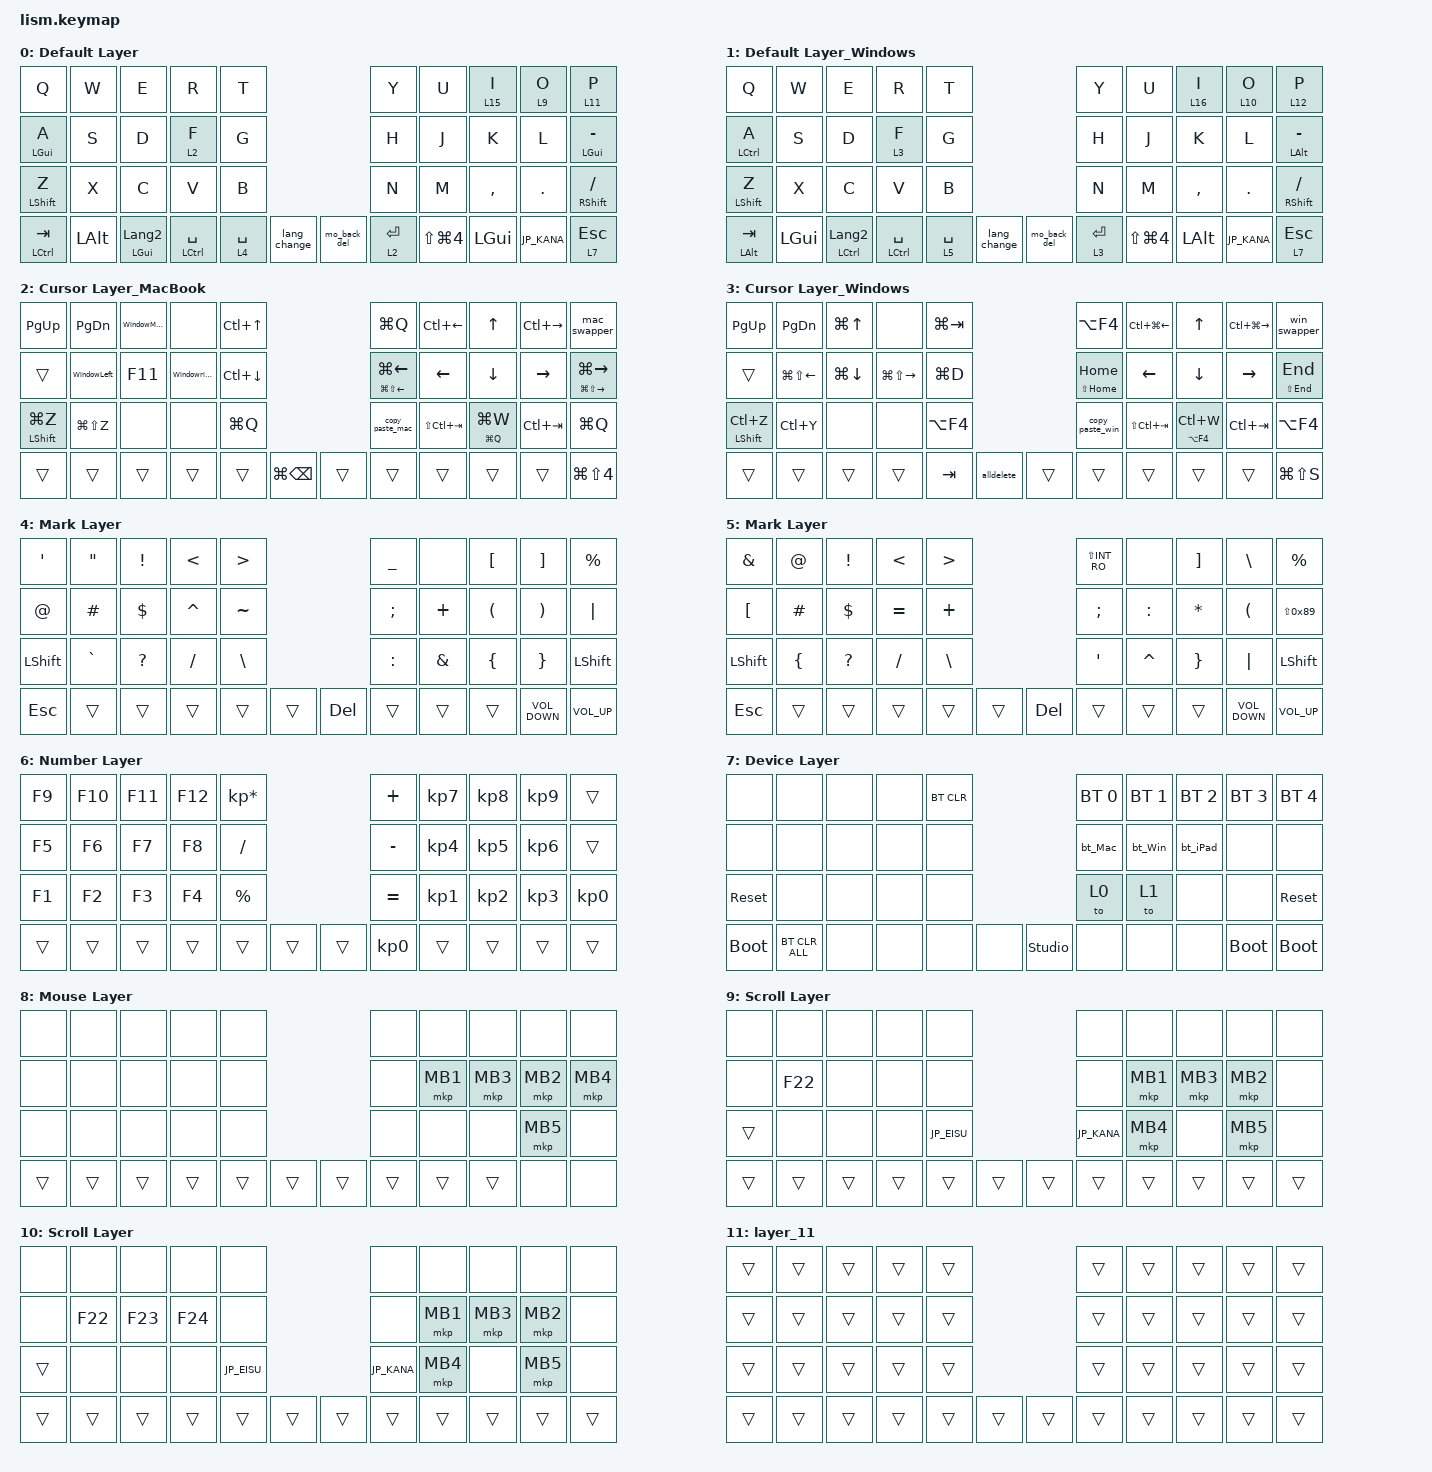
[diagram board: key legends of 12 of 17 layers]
#define ZMK_POINTING_DEFAULT_SCRL_VAL 200

#include <dt-bindings/zmk/mouse.h>
#include <mouse-gesture.dtsi>
#include <behaviors.dtsi>
#include <dt-bindings/zmk/bt.h>
#include <dt-bindings/zmk/keys.h>
#include <dt-bindings/zmk/pointing.h>

// OS設定を日本語キーボードのまま使用するための変換定義

#define JP_DQUOTE       AT                // "
#define JP_AMPERSAND    CARET             // &
#define JP_QUOTE        AMPERSAND         // '
#define JP_EQUAL        UNDER             // =
#define JP_CARET        EQUAL             // ^
#define JP_YEN          0x89              // ¥
#define JP_PLUS         COLON             // +
#define JP_TILDE        PLUS              // ~
#define JP_PIPE         LS(0x89)          // |
#define JP_AT           LEFT_BRACKET      // @
#define JP_COLON        SINGLE_QUOTE      // :
#define JP_ASTERISK     DOUBLE_QUOTES     // *
#define JP_BACKQUOTE    LEFT_BRACE        // `
#define JP_UNDERSCORE   LS(0x87)          // _
#define JP_LBRACKET     RIGHT_BRACKET     // [
#define JP_RBRACKET     BACKSLASH         // ]
#define JP_LPAREN       ASTERISK          // (
#define JP_RPAREN       LEFT_PARENTHESIS  // )
#define JP_LBRACE       RIGHT_BRACE       // {
#define JP_RBRACE       PIPE              // }
#define JP_KANA         LANGUAGE_1        // かな
#define JP_EISU         LANGUAGE_2        // 英数
#define JP_HANZEN       GRAVE             // 半角/全角

&mt {
    tapping-term-ms = <200>; /* タップ判定時間 */
    flavor = "balanced";
    quick-tap-ms = <250>; /* クイックタップ時間(連続タップ判定時間) */
};

&lt {
    tapping-term-ms = <180>;
    flavor = "balanced";
    quick-tap-ms = <250>;
};

/ {
    macros {
        emoji: emoji_macro {
            compatible = "zmk,behavior-macro";
            label = "EMOJI";
            #binding-cells = <0>;
            bindings =
                <&macro_press>,
                <&kp CAPSLOCK>,
                <&macro_tap>,
                <&kp E>,
                <&macro_release>,
                <&kp CAPSLOCK>;
        };

        bt_Mac: MacBook {
            compatible = "zmk,behavior-macro";
            #binding-cells = <0>;
            bindings = <&macro_tap>, <&bt BT_SEL 0>, <&macro_tap>, <&to 0>;

            label = "MACBOOKあ";
        };

        bt_Win: new_macro {
            compatible = "zmk,behavior-macro";
            #binding-cells = <0>;
            bindings = <&macro_tap>, <&bt BT_SEL 1>, <&macro_tap>, <&to 1>;

            label = "NEW_MACRO";
        };

        bt_iPad: _bt_ipad {
            compatible = "zmk,behavior-macro";
            #binding-cells = <0>;
            bindings = <&macro_tap>, <&bt BT_SEL 2>, <&macro_tap>, <&to 0>;

            label = "&BT_IPAD";
        };

        WindowMaximize: WindowMaximize {
            compatible = "zmk,behavior-macro";
            #binding-cells = <0>;
            bindings =
                <&macro_press>,
                <&kp LCTRL &kp LEFT_ALT>,
                <&macro_tap>,
                <&kp ENTER>,
                <&macro_release>,
                <&kp LCTRL &kp LEFT_ALT>;

            label = "WINDOWMAXIMIZE";
        };

        WindowLeft: WindowLeft {
            compatible = "zmk,behavior-macro";
            #binding-cells = <0>;
            bindings =
                <&macro_press>,
                <&kp LCTRL &kp LEFT_ALT>,
                <&macro_tap>,
                <&kp LEFT_ARROW>,
                <&macro_release>,
                <&kp LCTRL &kp LEFT_ALT>;

            label = "WINDOWLEFT";
        };

        Windowright: Windowright {
            compatible = "zmk,behavior-macro";
            #binding-cells = <0>;
            bindings =
                <&macro_press>,
                <&kp LCTRL &kp LEFT_ALT>,
                <&macro_tap>,
                <&kp RIGHT_ARROW>,
                <&macro_release>,
                <&kp LCTRL &kp LEFT_ALT>;

            label = "WINDOWRIGHT";
        };

        alldelete: alldelete {
            compatible = "zmk,behavior-macro";
            #binding-cells = <0>;
            bindings =
                <&macro_press>,
                <&kp LEFT_SHIFT>,
                <&macro_tap>,
                <&kp HOME>,
                <&macro_release>,
                <&kp LSHIFT>,
                <&macro_tap>,
                <&kp BACKSPACE>;

            label = "alldelete";
        };
    };

    behaviors {
        encoder_msc: sensor_rotate_msc {
            compatible = "zmk,behavior-sensor-rotate-var";
            #sensor-binding-cells = <2>;
            bindings = <&msc>, <&msc>;

            tap-ms = <20>;
        };

        encoder_kp: sensor_rotate_kp {
            compatible = "zmk,behavior-sensor-rotate-var";
            #sensor-binding-cells = <2>;
            bindings = <&kp>, <&kp>;
        };

        eisu_kana: eisu_kana {
            compatible = "zmk,behavior-tap-dance";
            label = "EISU_KANA";
            #binding-cells = <0>;
            bindings = <&lt 6 LANGUAGE_1>, <&kp LANGUAGE_2>;

            tapping-term-ms = <180>;
        };

        copy_paste_mac: copy_paste_mac {
            compatible = "zmk,behavior-tap-dance";
            label = "COPY_PASTE_MAC";
            #binding-cells = <0>;
            tapping-term-ms = <250>;
            bindings = <&mt LG(V) LG(C)>, <&kp LG(X)>;
        };

        copy_paste_win: copy_paste_win {
            compatible = "zmk,behavior-tap-dance";
            label = "COPY_PASTE_WIN";
            #binding-cells = <0>;
            tapping-term-ms = <250>;
            bindings = <&mt LC(V) LC(C)>, <&kp LC(X)>;
        };

        missionControl: missionControl {
            compatible = "zmk,behavior-tap-dance";
            label = "MISSIONCONTROL";
            #binding-cells = <0>;
            bindings = <&kp LC(UP_ARROW)>, <&kp LC(DOWN_ARROW)>;

            tapping-term-ms = <250>;
        };

        window_tab: window_tab {
            compatible = "zmk,behavior-tap-dance";
            label = "WINDOW_TAB";
            #binding-cells = <0>;
            bindings = <&kp LG(TAB)>, <&kp LG(D)>;

            tapping-term-ms = <300>;
        };

        command_c: command_c {
            compatible = "zmk,behavior-tap-dance";
            label = "COMMAND_C";
            #binding-cells = <0>;
            bindings = <&kp LG(C)>, <&kp LG(X)>;

            tapping-term-ms = <250>;
        };

        command_v: command_v {
            compatible = "zmk,behavior-tap-dance";
            label = "COMMAND_V";
            #binding-cells = <0>;
            bindings = <&kp LG(V)>, <&kp LG(LS(V))>;

            tapping-term-ms = <250>;
        };

        control_c: control_c {
            compatible = "zmk,behavior-tap-dance";
            label = "CONTROL_C";
            #binding-cells = <0>;
            bindings = <&kp LC(C)>, <&kp LC(X)>;

            tapping-term-ms = <250>;
        };

        control_v: control_v {
            compatible = "zmk,behavior-tap-dance";
            label = "CONTROL_V";
            #binding-cells = <0>;
            bindings = <&kp LC(LS(V))>, <&kp LG(V)>;

            tapping-term-ms = <250>;
        };

        mo_back_del: mo_back_del {
            compatible = "zmk,behavior-mod-morph";
            label = "MO_BACK_DEL";
            bindings = <&kp BACKSPACE>, <&kp DELETE>;

            #binding-cells = <0>;
            mods = <(MOD_LSFT|MOD_RSFT)>;
        };

        // 「マック・スワッパー」の定義

        mac_swapper: mac_swapper {
            compatible = "zmk,behavior-smart-toggle";
            #binding-cells = <0>;
            bindings = <&kp LGUI>, <&kp TAB>;

            // 1つ目がホールド(Cmd)、2つ目が連打用(Tab)
            // ignored-key-positions = <8>;     // 隣のキー（逆送り用）を指定。※環境に合わせて番号を調整してください
        };

        win_swapper: win_swapper {
            compatible = "zmk,behavior-smart-toggle";
            #binding-cells = <0>;
            bindings = <&kp LALT>, <&kp TAB>;

            // ignored-key-positions = <8>;
        };

        lang_change: lang_change {
            compatible = "zmk,behavior-mod-morph";
            label = "LANG_CHANGE";
            bindings = <&lt 6 LANGUAGE_1>, <&kp LANGUAGE_2>;

            #binding-cells = <0>;
            mods = <(MOD_LCTL|MOD_LGUI)>;
        };
    };

    combos {
        compatible = "zmk,combos";

        Tab {
            bindings = <&kp TAB>;
            key-positions = <11 12>;
        };

        Esc {
            bindings = <&kp ESC>;
            key-positions = <1 2>;
        };

        f10 {
            bindings = <&kp F10>;
            key-positions = <22 23>;
        };

        TAB_right {
            bindings = <&kp TAB>;
            key-positions = <18 17>;
            layers = <0 1 8>;
        };

        layer13 {
            bindings = <&lt 13 LG(TAB)>;
            key-positions = <8 9>;
            layers = <0>;
        };

        layer14 {
            bindings = <&lt 14 LA(TAB)>;
            key-positions = <8 9>;
            layers = <1>;
        };

        Spotlight {
            bindings = <&kp LG(SPACE)>;
            key-positions = <7 8>;
            layers = <0>;
        };

        search {
            bindings = <&kp LEFT_GUI>;
            key-positions = <7 8>;
            layers = <1>;
        };

        missioncontrol {
            bindings = <&missionControl>;
            key-positions = <7 8>;
            layers = <2>;
        };

        window_tab {
            bindings = <&window_tab>;
            key-positions = <7 8>;
            layers = <3>;
        };

        command_c {
            bindings = <&command_c>;
            key-positions = <17 16>;
            layers = <2>;
        };

        command_v {
            bindings = <&command_v>;
            key-positions = <17 18>;
            layers = <2>;
        };

        control_c {
            bindings = <&control_c>;
            key-positions = <17 16>;
            layers = <3>;
        };

        control_v {
            bindings = <&control_v>;
            key-positions = <17 18>;
            layers = <3>;
        };

        command_z {
            bindings = <&kp LG(Z)>;
            key-positions = <20 21>;
            layers = <0>;
        };

        control_z {
            bindings = <&kp LC(Z)>;
            key-positions = <20 21>;
            layers = <1>;
        };

        command_y {
            bindings = <&kp LG(LS(Z))>;
            key-positions = <21 22>;
            layers = <0>;
        };

        control_y {
            bindings = <&kp LC(Y)>;
            key-positions = <21 22>;
            layers = <1>;
        };

        Layer7 {
            bindings = <&mo 7>;
            key-positions = <30 31>;
        };
    };

    keymap {
        compatible = "zmk,keymap";

        default_layer {
            display-name = "Default Layer";
            bindings = <
&kp Q             &kp W         &kp E                    &kp R            &kp T                                      &kp Y        &kp U           &lt 15 I      &lt 9 O      &lt 11 P
&mt LEFT_GUI A    &kp S         &kp D                    &lt 2 F          &kp G                                      &kp H        &kp J           &kp K         &kp L        &mt LEFT_GUI MINUS
&mt LEFT_SHIFT Z  &kp X         &kp C                    &kp V            &kp B                                      &kp N        &kp M           &kp COMMA     &kp DOT      &mt RIGHT_SHIFT SLASH
&mt LCTRL TAB     &kp LEFT_ALT  &mt LEFT_GUI LANGUAGE_2  &mt LCTRL SPACE  &lt 4 SPACE  &lang_change    &mo_back_del  &lt 2 ENTER  &kp LS(LG(N4))  &kp LEFT_GUI  &kp JP_KANA  &lt 7 ESC
            >;

            sensor-bindings = <&encoder_msc SCRL_DOWN SCRL_UP>;
        };

        layer_1 {
            display-name = "Default Layer_Windows";
            bindings = <
&kp Q             &kp W         &kp E                 &kp R            &kp T                                      &kp Y        &kp U           &lt 16 I      &lt 10 O     &lt 12 P
&mt LCTRL A       &kp S         &kp D                 &lt 3 F          &kp G                                      &kp H        &kp J           &kp K         &kp L        &mt LEFT_ALT MINUS
&mt LEFT_SHIFT Z  &kp X         &kp C                 &kp V            &kp B                                      &kp N        &kp M           &kp COMMA     &kp DOT      &mt RIGHT_SHIFT SLASH
&mt LEFT_ALT TAB  &kp LEFT_GUI  &mt LCTRL LANGUAGE_2  &mt LCTRL SPACE  &lt 5 SPACE  &lang_change    &mo_back_del  &lt 3 ENTER  &kp LS(LG(N4))  &kp LEFT_ALT  &kp JP_KANA  &lt 7 ESC
            >;

            sensor-bindings = <&encoder_msc SCRL_UP SCRL_DOWN>;
        };

        layer_2 {
            display-name = "Cursor Layer_MacBook";
            bindings = <
&kp PAGE_UP      &kp PAGE_DOWN  &WindowMaximize  &none         &kp LC(UP_ARROW)                                 &kp LG(Q)                              &kp LC(LEFT_ARROW)  &kp UP           &kp LC(RIGHT_ARROW)  &mac_swapper
&trans           &WindowLeft    &kp F11          &Windowright  &kp LC(DOWN_ARROW)                               &mt LG(LS(LEFT_ARROW)) LG(LEFT_ARROW)  &kp LEFT_ARROW      &kp DOWN_ARROW   &kp RIGHT_ARROW      &mt LG(LS(RIGHT_ARROW)) LG(RIGHT_ARROW)
&mt LSHFT LG(Z)  &kp LG(LS(Z))  &none            &none         &kp LG(Q)                                        &copy_paste_mac                        &kp LS(LC(TAB))     &mt LG(Q) LG(W)  &kp LC(TAB)          &kp LG(Q)
&trans           &trans         &trans           &trans        &trans              &kp LG(BACKSPACE)    &trans  &trans                                 &trans              &trans           &trans               &kp LG(LS(NUMBER_4))
            >;

            sensor-bindings = <&encoder_kp LS(LC(TAB)) LC(TAB)>;
        };

        layer_3 {
            display-name = "Cursor Layer_Windows";
            bindings = <
&kp PAGE_UP           &kp PAGE_DOWN           &kp LG(UP_ARROW)    &none                    &kp LG(TAB)                        &kp LA(F4)         &kp LC(LG(LEFT_ARROW))  &kp UP            &kp LC(LG(RIGHT_ARROW))  &win_swapper
&trans                &kp LG(LS(LEFT_ARROW))  &kp LG(DOWN_ARROW)  &kp LG(LS(RIGHT_ARROW))  &kp LG(D)                          &mt LS(HOME) HOME  &kp LEFT_ARROW          &kp DOWN_ARROW    &kp RIGHT_ARROW          &mt LS(END) END
&mt LEFT_SHIFT LC(Z)  &kp LC(Y)               &none               &none                    &kp LA(F4)                         &copy_paste_win    &kp LS(LC(TAB))         &mt LA(F4) LC(W)  &kp LC(TAB)              &kp LA(F4)
&trans                &trans                  &trans              &trans                   &kp TAB      &alldelete    &trans  &trans             &trans                  &trans            &trans                   &kp LG(LS(S))
            >;

            sensor-bindings = <&encoder_kp LS(LC(TAB)) LC(TAB)>;
        };

        layer_4 {
            display-name = "Mark Layer";
            bindings = <
&kp SINGLE_QUOTE  &kp DOUBLE_QUOTES  &kp EXCLAMATION  &kp LESS_THAN  &kp GREATER_THAN                        &kp UNDERSCORE  &none          &kp LEFT_BRACKET      &kp RIGHT_BRACKET      &kp PERCENT
&kp AT_SIGN       &kp HASH           &kp DOLLAR       &kp CARET      &kp TILDE                               &kp SEMICOLON   &kp PLUS       &kp LEFT_PARENTHESIS  &kp RIGHT_PARENTHESIS  &kp PIPE
&kp LEFT_SHIFT    &kp GRAVE          &kp QUESTION     &kp SLASH      &kp BACKSLASH                           &kp COLON       &kp AMPERSAND  &kp LEFT_BRACE        &kp RIGHT_BRACE        &kp LSHFT
&kp ESC           &trans             &trans           &trans         &trans            &trans    &kp DELETE  &trans          &trans         &trans                &kp C_VOLUME_DOWN      &kp C_VOLUME_UP
            >;

            sensor-bindings = <&encoder_kp LC(LS(TAB)) LC(TAB)>;
        };

        layer_5 {
            display-name = "Mark Layer";
            bindings = <
&kp AMPERSAND     &kp AT          &kp EXCLAMATION  &kp LESS_THAN  &kp GREATER_THAN                        &kp LS(INT_RO)    &none      &kp RIGHT_BRACKET  &kp BACKSLASH         &kp PERCENT
&kp LEFT_BRACKET  &kp HASH        &kp DOLLAR       &kp EQUAL      &kp PLUS                                &kp SEMICOLON     &kp COLON  &kp ASTERISK       &kp LEFT_PARENTHESIS  &kp LS(0x89)
&kp LEFT_SHIFT    &kp LEFT_BRACE  &kp QUESTION     &kp SLASH      &kp BACKSLASH                           &kp SINGLE_QUOTE  &kp CARET  &kp RIGHT_BRACE    &kp PIPE              &kp LEFT_SHIFT
&kp ESC           &trans          &trans           &trans         &trans            &trans    &kp DELETE  &trans            &trans     &trans             &kp C_VOLUME_DOWN     &kp C_VOLUME_UP
            >;
        };

        layer_6 {
            display-name = "Number Layer";
            bindings = <
&kp F9  &kp F10  &kp F11  &kp F12  &kp KP_MULTIPLY                    &kp PLUS         &kp KP_NUMBER_7  &kp KP_NUMBER_8  &kp KP_NUMBER_9  &trans
&kp F5  &kp F6   &kp F7   &kp F8   &kp SLASH                          &kp MINUS        &kp KP_NUMBER_4  &kp KP_NUMBER_5  &kp KP_NUMBER_6  &trans
&kp F1  &kp F2   &kp F3   &kp F4   &kp PERCENT                        &kp EQUAL        &kp KP_NUMBER_1  &kp KP_NUMBER_2  &kp KP_NUMBER_3  &kp KP_NUMBER_0
&trans  &trans   &trans   &trans   &trans           &trans    &trans  &kp KP_NUMBER_0  &trans           &trans           &trans           &trans
            >;

            sensor-bindings = <&encoder_kp C_VOL_UP C_VOL_DN>;
        };

        layer_7 {
            display-name = "Device Layer";
            bindings = <
&none        &none           &none  &none  &bt BT_CLR                           &bt BT_SEL 0  &bt BT_SEL 1  &bt BT_SEL 2  &bt BT_SEL 3  &bt BT_SEL 4
&none        &none           &none  &none  &none                                &bt_Mac       &bt_Win       &bt_iPad      &none         &none
&sys_reset   &none           &none  &none  &none                                &to 0         &to 1         &none         &none         &sys_reset
&bootloader  &bt BT_CLR_ALL  &none  &none  &none       &none    &studio_unlock  &none         &none         &none         &bootloader   &bootloader
            >;
        };

        layer_8 {
            display-name = "Mouse Layer";
            bindings = <
&none   &none   &none   &none   &none                     &none   &none     &none     &none     &none
&none   &none   &none   &none   &none                     &none   &mkp MB1  &mkp MB3  &mkp MB2  &mkp MB4
&none   &none   &none   &none   &none                     &none   &none     &none     &mkp MB5  &none
&trans  &trans  &trans  &trans  &trans  &trans    &trans  &trans  &trans    &trans    &none     &none
            >;
        };

        layer_9 {
            display-name = "Scroll Layer";
            bindings = <
&none   &none    &none   &none   &none                          &none        &none     &none     &none     &none
&none   &kp F22  &none   &none   &none                          &none        &mkp MB1  &mkp MB3  &mkp MB2  &none
&trans  &none    &none   &none   &kp JP_EISU                    &kp JP_KANA  &mkp MB4  &none     &mkp MB5  &none
&trans  &trans   &trans  &trans  &trans       &trans    &trans  &trans       &trans    &trans    &trans    &trans
            >;

            sensor-bindings = <&inc_dec_kp LEFT_ARROW RIGHT_ARROW>;
        };

        layer_10 {
            display-name = "Scroll Layer";
            bindings = <
&none   &none    &none    &none    &none                          &none        &none     &none     &none     &none
&none   &kp F22  &kp F23  &kp F24  &none                          &none        &mkp MB1  &mkp MB3  &mkp MB2  &none
&trans  &none    &none    &none    &kp JP_EISU                    &kp JP_KANA  &mkp MB4  &none     &mkp MB5  &none
&trans  &trans   &trans   &trans   &trans       &trans    &trans  &trans       &trans    &trans    &trans    &trans
            >;

            sensor-bindings = <&encoder_kp LEFT_ARROW RIGHT_ARROW>;
        };

        layer_11 {
            bindings = <
&trans  &trans  &trans  &trans  &trans                    &trans  &trans  &trans  &trans  &trans
&trans  &trans  &trans  &trans  &trans                    &trans  &trans  &trans  &trans  &trans
&trans  &trans  &trans  &trans  &trans                    &trans  &trans  &trans  &trans  &trans
&trans  &trans  &trans  &trans  &trans  &trans    &trans  &trans  &trans  &trans  &trans  &trans
            >;

            sensor-bindings = <&encoder_kp UP_ARROW DOWN_ARROW>;
        };

        layer_12 {
            bindings = <
&trans  &trans  &trans  &trans  &trans                    &trans  &trans  &trans  &trans  &trans
&trans  &trans  &trans  &trans  &trans                    &trans  &trans  &trans  &trans  &trans
&trans  &trans  &trans  &trans  &trans                    &trans  &trans  &trans  &trans  &trans
&trans  &trans  &trans  &trans  &trans  &trans    &trans  &trans  &trans  &trans  &trans  &trans
            >;

            sensor-bindings = <&encoder_kp UP_ARROW DOWN_ARROW>;
        };

        layer_13 {
            bindings = <
&trans  &trans  &trans  &trans  &trans                    &trans  &trans  &trans  &trans  &trans
&trans  &trans  &trans  &trans  &trans                    &trans  &trans  &trans  &trans  &trans
&trans  &trans  &trans  &trans  &trans                    &trans  &trans  &trans  &trans  &trans
&trans  &trans  &trans  &trans  &trans  &trans    &trans  &trans  &trans  &trans  &trans  &trans
            >;
        };

        layer_14 {
            bindings = <
&trans  &trans  &trans  &trans  &trans                    &trans  &trans  &trans  &trans  &trans
&trans  &trans  &trans  &trans  &trans                    &trans  &trans  &trans  &trans  &trans
&trans  &trans  &trans  &trans  &trans                    &trans  &trans  &trans  &trans  &trans
&trans  &trans  &trans  &trans  &trans  &trans    &trans  &trans  &trans  &trans  &trans  &trans
            >;
        };

        layer_15 {
            bindings = <
&trans  &trans  &trans  &trans  &trans                    &trans  &trans  &trans  &trans  &trans
&trans  &trans  &trans  &trans  &trans                    &trans  &trans  &trans  &trans  &trans
&trans  &trans  &trans  &trans  &trans                    &trans  &trans  &trans  &trans  &trans
&trans  &trans  &trans  &trans  &trans  &trans    &trans  &trans  &trans  &trans  &trans  &trans
            >;
        };

        layer_16 {
            bindings = <
&trans  &trans  &trans  &trans  &trans                    &trans  &trans  &trans  &trans  &trans
&trans  &trans  &trans  &trans  &trans                    &trans  &trans  &trans  &trans  &trans
&trans  &trans  &trans  &trans  &trans                    &trans  &trans  &trans  &trans  &trans
&trans  &trans  &trans  &trans  &trans  &trans    &trans  &trans  &trans  &trans  &trans  &trans
            >;
        };
    };
};

// ジェスチャー設定 
// L11用のパターン

&zip_mouse_gesture_1 {
    enable-eager-mode;
    always-active;
    stroke-size = <5>;
    movement-threshold = <6>;
    idle-timeout-ms = <100>;
    gesture-cooldown-ms = <120>;

    prev_tab_l11 {
        pattern = <GESTURE_LEFT>;
        bindings = <&kp LC(TAB)>;
    };

    next_tab_l11 {
        pattern = <GESTURE_RIGHT>;
        bindings = <&kp LC(LS(TAB))>;
    };

    Create_tab_l11 {
        pattern = <GESTURE_UP>;
        bindings = <&kp LG(W)>;
    };

    close_tab_l11 {
        pattern = <GESTURE_DOWN>;
        bindings = <&kp LG(T)>;
    };
};

// L12用のパターン

&zip_mouse_gesture_2 {
    enable-eager-mode;
    always-active;
    stroke-size = <5>;
    movement-threshold = <6>;
    idle-timeout-ms = <100>;
    gesture-cooldown-ms = <120>;

    prev_tab_l12 {
        pattern = <GESTURE_LEFT>;
        bindings = <&kp LC(TAB)>;
    };

    next_tab_l12 {
        pattern = <GESTURE_RIGHT>;
        bindings = <&kp LC(LS(TAB))>;
    };

    Create_tab_l12 {
        pattern = <GESTURE_UP>;
        bindings = <&kp LC(W)>;
    };

    close_tab_l12 {
        pattern = <GESTURE_DOWN>;
        bindings = <&kp LC(T)>;
    };
};

// L13用のパターン(ウィンドウ操作_Mac)

&zip_mouse_gesture_3 {
    enable-eager-mode;
    always-active;
    stroke-size = <5>;
    movement-threshold = <6>;
    idle-timeout-ms = <100>;
    gesture-cooldown-ms = <120>;

    vdesk_prev_13 {
        pattern = <GESTURE_LEFT>;
        bindings = <&kp LC(RIGHT)>;
    };

    vdesk_next_13 {
        pattern = <GESTURE_RIGHT>;
        bindings = <&kp LC(LEFT)>;
    };

    view_window_13 {
        pattern = <GESTURE_UP>;
        bindings = <&kp LC(DOWN)>;
    };

    view_application_13 {
        pattern = <GESTURE_DOWN>;
        bindings = <&kp LC(UP)>;
    };
};

// L14用のパターン(ウィンドウ操作_win)

&zip_mouse_gesture_4 {
    enable-eager-mode;
    always-active;
    stroke-size = <5>;
    movement-threshold = <6>;
    idle-timeout-ms = <100>;
    gesture-cooldown-ms = <120>;

    vdesk_prev_14 {
        pattern = <GESTURE_LEFT>;
        bindings = <&kp LG(LC(RIGHT))>;
    };

    vdesk_next_14 {
        pattern = <GESTURE_RIGHT>;
        bindings = <&kp LG(LC(LEFT))>;
    };

    view_window_14 {
        pattern = <GESTURE_UP>;
        bindings = <&kp LG(D)>;
    };

    view_application_14 {
        pattern = <GESTURE_DOWN>;
        bindings = <&kp LG(TAB)>;
    };
};

// L15用のパターン

&zip_mouse_gesture_5 {
    enable-eager-mode;
    always-active;
    stroke-size = <5>;
    movement-threshold = <6>;
    idle-timeout-ms = <100>;
    gesture-cooldown-ms = <120>;

    copy_15 {
        pattern = <GESTURE_LEFT>;
        bindings = <&kp LG(V)>;
    };

    paste_15 {
        pattern = <GESTURE_RIGHT>;
        bindings = <&kp LG(C)>;
    };

    focus_url_15 {
        pattern = <GESTURE_UP>;
        bindings = <&kp LG(SPACE)>;
    };

    search_15 {
        pattern = <GESTURE_DOWN>;
        bindings = <&kp LG(L)>;
    };
};

// L16用のパターン

&zip_mouse_gesture_6 {
    enable-eager-mode;
    always-active;
    stroke-size = <5>;
    movement-threshold = <6>;
    idle-timeout-ms = <100>;
    gesture-cooldown-ms = <120>;

    copy_16 {
        pattern = <GESTURE_LEFT>;
        bindings = <&kp LC(V)>;
    };

    paste_16 {
        pattern = <GESTURE_RIGHT>;
        bindings = <&kp LC(C)>;
    };

    focus_url_16 {
        pattern = <GESTURE_UP>;
        bindings = <&kp LC(GUI)>;
    };

    search_16 {
        pattern = <GESTURE_DOWN>;
        bindings = <&kp LC(L)>;
    };
};
